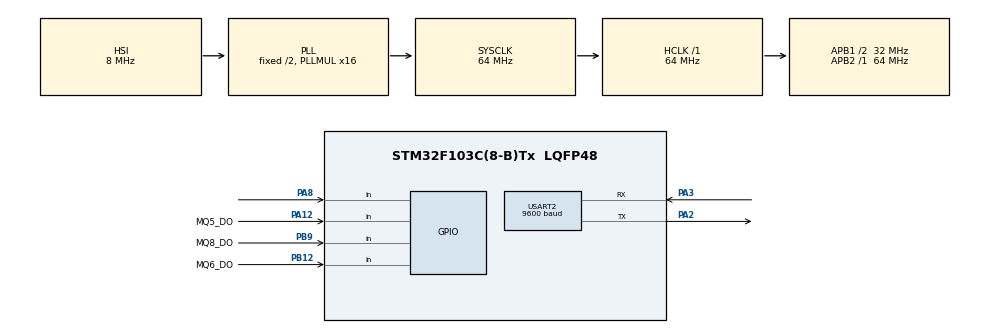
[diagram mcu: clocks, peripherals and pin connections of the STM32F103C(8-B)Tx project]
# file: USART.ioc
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Mcu.Family=STM32F1
Mcu.Name=STM32F103C(8-B)Tx
Mcu.Package=LQFP48
NVIC.PriorityGroup=NVIC_PRIORITYGROUP_4
PA12.GPIO_Label=MQ5_DO
PA12.GPIO_PuPd=GPIO_PULLUP
PA12.Signal=GPIO_Input
PB9.GPIO_Label=MQ8_DO
PB9.GPIO_PuPd=GPIO_PULLUP
PB9.Signal=GPIO_Input
PB12.GPIO_Label=MQ6_DO
PB12.GPIO_PuPd=GPIO_PULLUP
PB12.Signal=GPIO_Input
PA3.Mode=Asynchronous
PA3.Signal=USART2_RX
PA13.Mode=Serial_Wire
PA13.Signal=SYS_JTMS-SWDIO
PA14.Mode=Serial_Wire
PA14.Signal=SYS_JTCK-SWCLK
PA8.GPIO_PuPd=GPIO_PULLUP
PA8.Signal=GPIO_Input
PA2.Mode=Asynchronous
PA2.Signal=USART2_TX
ProjectManager.HeapSize=0x200
ProjectManager.StackSize=0x400
ProjectManager.TargetToolchain=MDK-ARM V5.32
RCC.AHBFreq_Value=64000000
RCC.APB1CLKDivider=RCC_HCLK_DIV2
RCC.APB1Freq_Value=32000000
RCC.APB1TimFreq_Value=64000000
RCC.APB2Freq_Value=64000000
RCC.APB2TimFreq_Value=64000000
RCC.HCLKFreq_Value=64000000
RCC.PLLMUL=RCC_PLL_MUL16
RCC.SYSCLKFreq_VALUE=64000000
RCC.SYSCLKSource=RCC_SYSCLKSOURCE_PLLCLK
RCC.USBFreq_Value=64000000
USART2.BaudRate=9600
USART2.VirtualMode=VM_ASYNC
board=custom

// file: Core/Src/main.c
/* USER CODE BEGIN Header */
/**
  ******************************************************************************
  * @file           : main.c
  * @brief          : Main program body
  ******************************************************************************
  * @attention
  *
  * Copyright (c) 2026 STMicroelectronics.
  * All rights reserved.
  *
  * This software is licensed under terms that can be found in the LICENSE file
  * in the root directory of this software component.
  * If no LICENSE file comes with this software, it is provided AS-IS.
  *
  ******************************************************************************
  */
/* USER CODE END Header */
#include "main.h"

/* USER CODE BEGIN Includes */
#include "mq_lora_app.h"
/* USER CODE END Includes */

UART_HandleTypeDef huart2;

void SystemClock_Config(void);
static void MX_GPIO_Init(void);
static void MX_USART2_UART_Init(void);

int main(void)
{

  /* MCU Configuration--------------------------------------------------------*/

  /* Reset of all peripherals, Initializes the Flash interface and the Systick. */
  HAL_Init();

  /* Configure the system clock */
  SystemClock_Config();

  /* Initialize all configured peripherals */
  MX_GPIO_Init();
  MX_USART2_UART_Init();
  /* USER CODE BEGIN 2 */
  MqLoRaApp_Init(&huart2);
  /* USER CODE END 2 */

  /* Infinite loop */
  while (1)
  {

    /* USER CODE BEGIN 3 */
    MqLoRaApp_Process();
  }
  /* USER CODE END 3 */
}

void SystemClock_Config(void)
{
  RCC_OscInitTypeDef RCC_OscInitStruct = {0};
  RCC_ClkInitTypeDef RCC_ClkInitStruct = {0};

  /** Initializes the RCC Oscillators according to the specified parameters
  * in the RCC_OscInitTypeDef structure.
  */
  RCC_OscInitStruct.OscillatorType = RCC_OSCILLATORTYPE_HSI;
  RCC_OscInitStruct.HSIState = RCC_HSI_ON;
  RCC_OscInitStruct.HSICalibrationValue = RCC_HSICALIBRATION_DEFAULT;
  RCC_OscInitStruct.PLL.PLLState = RCC_PLL_ON;
  RCC_OscInitStruct.PLL.PLLSource = RCC_PLLSOURCE_HSI_DIV2;
  RCC_OscInitStruct.PLL.PLLMUL = RCC_PLL_MUL16;
  if (HAL_RCC_OscConfig(&RCC_OscInitStruct) != HAL_OK)
  {
    Error_Handler();
  }

  /** Initializes the CPU, AHB and APB buses clocks
  */
  RCC_ClkInitStruct.ClockType = RCC_CLOCKTYPE_HCLK|RCC_CLOCKTYPE_SYSCLK
                              |RCC_CLOCKTYPE_PCLK1|RCC_CLOCKTYPE_PCLK2;
  RCC_ClkInitStruct.SYSCLKSource = RCC_SYSCLKSOURCE_PLLCLK;
  RCC_ClkInitStruct.AHBCLKDivider = RCC_SYSCLK_DIV1;
  RCC_ClkInitStruct.APB1CLKDivider = RCC_HCLK_DIV2;
  RCC_ClkInitStruct.APB2CLKDivider = RCC_HCLK_DIV1;

  if (HAL_RCC_ClockConfig(&RCC_ClkInitStruct, FLASH_LATENCY_2) != HAL_OK)
  {
    Error_Handler();
  }
}

static void MX_USART2_UART_Init(void)
{

  huart2.Instance = USART2;
  huart2.Init.BaudRate = 9600;
  huart2.Init.WordLength = UART_WORDLENGTH_8B;
  huart2.Init.StopBits = UART_STOPBITS_1;
  huart2.Init.Parity = UART_PARITY_NONE;
  huart2.Init.Mode = UART_MODE_TX_RX;
  huart2.Init.HwFlowCtl = UART_HWCONTROL_NONE;
  huart2.Init.OverSampling = UART_OVERSAMPLING_16;
  if (HAL_UART_Init(&huart2) != HAL_OK)
  {
    Error_Handler();
  }

}

static void MX_GPIO_Init(void)
{
  GPIO_InitTypeDef GPIO_InitStruct = {0};

  /* GPIO Ports Clock Enable */
  __HAL_RCC_GPIOA_CLK_ENABLE();
  __HAL_RCC_GPIOB_CLK_ENABLE();

  /* MQ5 DO: PA12, active low. */
  GPIO_InitStruct.Pin = MQ5_DO_Pin;
  GPIO_InitStruct.Mode = GPIO_MODE_INPUT;
  GPIO_InitStruct.Pull = GPIO_PULLUP;
  HAL_GPIO_Init(MQ5_DO_GPIO_Port, &GPIO_InitStruct);

  /* MQ8 DO: PB9; MQ6 DO: PB12, active low. */
  GPIO_InitStruct.Pin = MQ8_DO_Pin|MQ6_DO_Pin;
  HAL_GPIO_Init(GPIOB, &GPIO_InitStruct);

  /* Keep PA8 available for the existing auxiliary input. */
  GPIO_InitStruct.Pin = GPIO_PIN_8;
  HAL_GPIO_Init(GPIOA, &GPIO_InitStruct);

}

void Error_Handler(void)
{
  __disable_irq();
  while (1)
  {
  }
}
